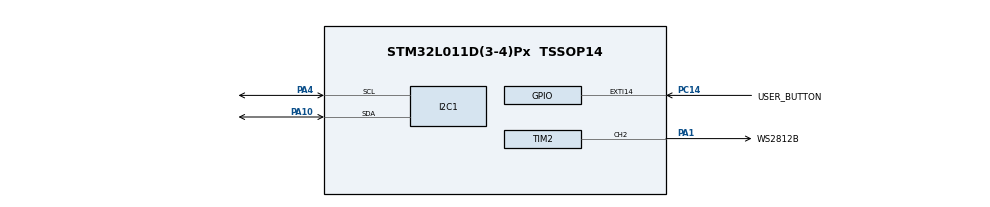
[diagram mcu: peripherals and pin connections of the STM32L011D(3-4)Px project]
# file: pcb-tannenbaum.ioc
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Mcu.Family=STM32L0
RCC.MSI_VALUE=2097000
I2C1.Speed=100
SYS.PVDLevel=PWR_PVDLEVEL_3
PA10.Mode=I2C
TIM2.Channel-PWM\ Generation2\ CH2=TIM_CHANNEL_2
PC14-OSC32_IN.Signal=GPXTI14
RCC.SYSCLKSource=RCC_SYSCLKSOURCE_PLLCLK
ProjectManager.StackSize=0x180
Dma.TIM2_CH2.0.Priority=DMA_PRIORITY_VERY_HIGH
Dma.TIM2_CH2.0.PeriphDataAlignment=DMA_PDATAALIGN_WORD
PA13.Signal=SYS_SWDIO
RCC.HSI16_VALUE=16000000
SH.S_TIM2_CH2.0=TIM2_CH2,PWM Generation2 CH2
Dma.TIM2_CH2.0.MemInc=DMA_MINC_ENABLE
PA4.Mode=I2C
ProjectManager.TargetToolchain=STM32CubeIDE
RCC.HCLKFreq_Value=32000000
RCC.APB2TimFreq_Value=32000000
I2C1.Timing=0x00707CBB
RCC.LSE_VALUE=32768
PA1.GPIO_PuPd=GPIO_PULLDOWN
PA1.Signal=S_TIM2_CH2
RCC.AHBFreq_Value=32000000
RCC.HSE_VALUE=8000000
Dma.TIM2_CH2.0.Mode=DMA_CIRCULAR
board=custom
RCC.VCOOutputFreq_Value=64000000
RCC.PLLMUL=RCC_PLLMUL_4
PC14-OSC32_IN.GPIO_ModeDefaultEXTI=GPIO_MODE_IT_FALLING
RCC.APB2Freq_Value=32000000
VP_TIM2_VS_ClockSourceINT.Mode=Internal
PA14.Mode=Serial_Wire
NVIC.TIM2_IRQn=true\:0\:0\:false\:false\:true\:true\:false
PA1.GPIO_Label=WS2812B
TIM2.Period=40
PA13.Mode=Serial_Wire
Mcu.Name=STM32L011D(3-4)Px
Dma.TIM2_CH2.0.MemDataAlignment=DMA_MDATAALIGN_BYTE
Dma.TIM2_CH2.0.Instance=DMA1_Channel3
PA4.Signal=I2C1_SCL
RCC.SYSCLKFreq_VALUE=32000000
Mcu.Package=TSSOP14
TIM2.Prescaler=0
TIM2.OC2Preload_PWM=ENABLE
PA10.Signal=I2C1_SDA
PA14.Signal=SYS_SWCLK
ProjectManager.HeapSize=0x000
VP_SYS_V_PVD_IN.Mode=Mode_PVD_Int
TIM2.Pulse-PWM\ Generation2\ CH2=0
RCC.HSI_VALUE=16000000
NVIC.DMA1_Channel2_3_IRQn=true\:0\:0\:false\:false\:true\:true\:false
RCC.APB1TimFreq_Value=32000000
PC14-OSC32_IN.GPIO_PuPd=GPIO_PULLUP
PC14-OSC32_IN.GPIO_Label=USER_BUTTON
RCC.APB1Freq_Value=32000000
Dma.Request0=TIM2_CH2
Dma.TIM2_CH2.0.Direction=DMA_MEMORY_TO_PERIPH
Dma.TIM2_CH2.0.PeriphInc=DMA_PINC_DISABLE
NVIC.EXTI4_15_IRQn=true\:0\:0\:false\:false\:true\:true\:true

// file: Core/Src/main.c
/* USER CODE BEGIN Header */
/**
  ******************************************************************************
  * @file           : main.c
  * @brief          : Main program body
  ******************************************************************************
  * @attention
  *
  * <h2><center>&copy; Copyright (c) 2020 STMicroelectronics.
  * All rights reserved.</center></h2>
  *
  * This software component is licensed by ST under BSD 3-Clause license,
  * the "License"; You may not use this file except in compliance with the
  * License. You may obtain a copy of the License at:
  *                        opensource.org/licenses/BSD-3-Clause
  *
  ******************************************************************************
  */
/* USER CODE END Header */
#include "main.h"
#include "dma.h"
#include "i2c.h"
#include "tim.h"
#include "gpio.h"

/* USER CODE BEGIN Includes */
#include <application.h>
/* USER CODE END Includes */

void SystemClock_Config(void);

int main(void)
{

  /* MCU Configuration--------------------------------------------------------*/

  /* Reset of all peripherals, Initializes the Flash interface and the Systick. */

  LL_APB2_GRP1_EnableClock(LL_APB2_GRP1_PERIPH_SYSCFG);
  LL_APB1_GRP1_EnableClock(LL_APB1_GRP1_PERIPH_PWR);

  /* System interrupt init*/

  /** PVD Configuration
  */
  LL_PWR_SetPVDLevel(LL_PWR_PVDLEVEL_3);
  /** Enable the PVD Output
  */
  LL_PWR_EnablePVD();

  /* Configure the system clock */
  SystemClock_Config();

  /* Initialize all configured peripherals */
  MX_GPIO_Init();
  MX_DMA_Init();
  MX_I2C1_Init();
  MX_TIM2_Init();

  /* Infinite loop */
  /* USER CODE BEGIN WHILE */
  while (1)
  {
  	application_main();
    /* USER CODE END WHILE */

  }
}

void SystemClock_Config(void)
{
  LL_FLASH_SetLatency(LL_FLASH_LATENCY_1);
  while(LL_FLASH_GetLatency()!= LL_FLASH_LATENCY_1)
  {
  }
  LL_PWR_SetRegulVoltageScaling(LL_PWR_REGU_VOLTAGE_SCALE1);
  LL_RCC_HSI_Enable();

   /* Wait till HSI is ready */
  while(LL_RCC_HSI_IsReady() != 1)
  {

  }
  LL_RCC_HSI_SetCalibTrimming(16);
  LL_RCC_PLL_ConfigDomain_SYS(LL_RCC_PLLSOURCE_HSI, LL_RCC_PLL_MUL_4, LL_RCC_PLL_DIV_2);
  LL_RCC_PLL_Enable();

   /* Wait till PLL is ready */
  while(LL_RCC_PLL_IsReady() != 1)
  {

  }
  LL_RCC_SetAHBPrescaler(LL_RCC_SYSCLK_DIV_1);
  LL_RCC_SetAPB1Prescaler(LL_RCC_APB1_DIV_1);
  LL_RCC_SetAPB2Prescaler(LL_RCC_APB2_DIV_1);
  LL_RCC_SetSysClkSource(LL_RCC_SYS_CLKSOURCE_PLL);

   /* Wait till System clock is ready */
  while(LL_RCC_GetSysClkSource() != LL_RCC_SYS_CLKSOURCE_STATUS_PLL)
  {

  }

  LL_Init1msTick(32000000);

  LL_SetSystemCoreClock(32000000);
  LL_RCC_SetI2CClockSource(LL_RCC_I2C1_CLKSOURCE_PCLK1);
}

void Error_Handler(void)
{
  __disable_irq();
  while (1)
  {
  }
}

/************************ (C) COPYRIGHT STMicroelectronics *****END OF FILE****/
